# CMS32M6510 register map
Vendor: CMS; Series: CMS32M6510; File version: 1.2
CPU: CM0+ r0p1, little endian, no MPU, no FPU, VTOR, 2 interrupt priority bits
Registers are 32-bit, read-write, reset 0x0 unless marked. A register's access mark holds for its fields unless they carry their own. Offsets are from the block's base; [hi:lo] are bit positions; {n}, {i} and the like mark numbered series; 'fields as' and 'values as' point back to an identical list.

## LVD — Voltage detector
Base 0x40020440
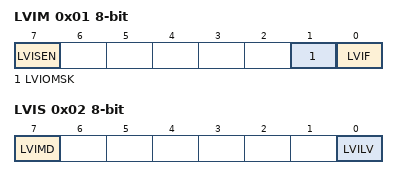
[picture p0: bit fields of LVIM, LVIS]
0x01 LVIM 8-bit — Voltage detection register
  [7] LVISEN ro — Enable rewritting LVIS register
    0=Disable (Disabling of rewriting the LVIS register); 1=Enable (Enabling of rewriting the LVIS register)
  [1] LVIOMSK ro — Mask status flag of LVD output
    0=Invalid (Mask of LVD output is invalid); 1=Valid (Mask of LVD output is valid)
  [0] LVIF ro — Voltage detection flag
    0=GE (Supply voltage (VDD) greater or equal to detection voltage (VLVD), or when LVD is off); 1=LT (Supply voltage (VDD) less than detection voltage (VLVD))
0x02 LVIS 8-bit — Voltage detection level register
  [7] LVIMD — Operation mode of voltage detection
    0=IRQ (interrupt mode); 1=reset mode
  [0] LVILV — LVD detection level
    0=High-voltage detection level (VLVDH); 1=Low (Low-voltage detection level (VLVDL or VLVD))

## PCBZ — Clock/Buzzer output controller
Base 0x40040FA0
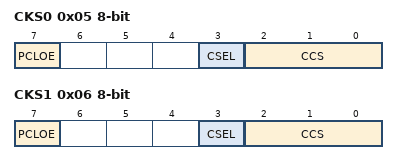
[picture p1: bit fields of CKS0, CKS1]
0x05 CKS0 8-bit — Clock output select registers 0
  [7] PCLOE — PCLBUZn pin output enable
  [3] CSEL — PCLBUZn output clock select
  [2:0] CCS — PCLBUZn output clock select
0x06 CKS1 8-bit — Clock output select registers 1
  fields as CKS0

## WDT — Watchdog Timer with window
Base 0x40020404
0x01 LOCKCTL 8-bit (reset mask 0x1) — Lockup Watchdog timer enable register
0x02 PRCR 8-bit — Lockup Watchdog timer enable protect register
0xBFD WDTE 8-bit (reset mask 0xAC) — Watchdog timer enable register

## TIMER0 — TIMER0 Decription
Base 0x40061000
Same registers: TIMER1 0x40061100
0x00 CON reset 0x20 — CON Description
0x04 LOAD — LOAD Description
0x08 VAL ro reset 0xFFFFFFFF — VAL Description
0x0C RIS ro — RIS Description
0x10 MIS ro — MIS Description
0x14 ICLR wo — ICLR Description
0x18 BGLOAD — BGLOAD Description

## LSITIMER
Base 0x40044B50
0x00 CON0 16-bit — Control Register 0

## EPWM — EPWM Decription
Base 0x40064200
0x00 CLKPSC — CLKPSC Description
0x04 CLKDIV — CLKDIV Description
0x08 CON — CON Description
0x0C CON2 — CON2 Description
0x10 CON3 — CON3 Description
{0x14+4i} PERIOD{i} (i=0..5) — PERIOD{i} Description
{0x2C+4i} CMPDAT{i} (i=0..5) — CMPDAT{i} Description
0x44 POREMAP — POREMAP Description
0x48 POEN reset 0x543210 — POEN Description
0x4C BRKCTL — BRKCTL Description
0x50 DTCTL — DTCTL Description
0x54 MASK — MASK Description
0x58 MASKNXT — MASKNXT Description
0x5C CMPTGD0 — CMPTGD0 Description
0x60 CMPTGD1 — CMPTGD1 Description
0x64 IMSC — IMSC Description
0x68 RIS ro — RIS Description
0x6C MIS ro — MIS Description
0x70 ICLR wo — ICLR Description
0x74 IFA — IFA Description
0x78 LOCK — LOCK Description

## CCP — CCP Decription
Base 0x40064280
0x00 CCPCON0 — CCPCON0 Description
0x04 CCPLOAD0 — CCPLOAD0 Description
0x08 CCPD0A — CCPD0A Description
0x0C CCPD0B — CCPD0B Description
0x10 CCPCON1 — CCPCON1 Description
0x14 CCPLOAD1 — CCPLOAD1 Description
0x18 CCPD1A — CCPD1A Description
0x1C CCPD1B — CCPD1B Description
0x40 CCPIMSC — CCPIMSC Description
0x44 CCPRIS ro — CCPRIS Description
0x48 CCPMIS ro — CCPMIS Description
0x4C CCPICLR wo — CCPICLR Description
0x50 CCPRUN — CCPRUN Description
0x54 CCPLOCK — CCPLOCK Description
0x58 CAPCON — CAPCON Description
0x5C CAPCHS — CAPCHS Description
{0x60+4i} CAP{i}DAT0 (i=0..3) — CAP{i}DAT0 Description

## UART0 — UART0 Decription
Base 0x40064000
0x00 UART0RBR ro — UART0RBR Description
0x04 UART0THR wo — UART0THR Description
0x08 UART0DLR reset 0x1 — UART0DLR Description
0x0C UART0IER — UART0IER Description
0x10 UART0IIR ro reset 0x1 — UART0IIR Description
0x14 UART0FCR wo — UART0FCR Description
0x18 UART0LCR — UART0LCR Description
0x1C UART0MCR — UART0MCR Description
0x20 UART0LSR ro reset 0x60 — UART0LSR Description
0x24 UART0MSR ro — UART0MSR Description
0x28 UART0SCR — UART0SCR Description
0x2C UART0EFR — UART0EFR Description
0x30 UART0XON1 — UART0XON1 Description
0x34 UART0XON2 — UART0XON2 Description
0x38 UART0XOFF1 — UART0XOFF1 Description
0x3C UART0END — UART0END Description

## Notices in the file
Copyright (C) 2012-2014 ARM Limited. All rights reserved.
Purpose: System Viewer Description (SVD) Example (Schema Version 1.1)
This is a description of a none-existent and incomplete device
for demonstration purposes only.
Redistribution and use in source and binary forms, with or without
modification, are permitted provided that the following conditions are met:
- Redistributions of source code must retain the above copyright
notice, this list of conditions and the following disclaimer.
- Redistributions in binary form must reproduce the above copyright
notice, this list of conditions and the following disclaimer in the
documentation and/or other materials provided with the distribution.
- Neither the name of ARM nor the names of its contributors may be used
to endorse or promote products derived from this software without
specific prior written permission.
THIS SOFTWARE IS PROVIDED BY THE COPYRIGHT HOLDERS AND CONTRIBUTORS "AS IS"
AND ANY EXPRESS OR IMPLIED WARRANTIES, INCLUDING, BUT NOT LIMITED TO, THE
IMPLIED WARRANTIES OF MERCHANTABILITY AND FITNESS FOR A PARTICULAR PURPOSE
ARE DISCLAIMED. IN NO EVENT SHALL COPYRIGHT HOLDERS AND CONTRIBUTORS BE
LIABLE FOR ANY DIRECT, INDIRECT, INCIDENTAL, SPECIAL, EXEMPLARY, OR
CONSEQUENTIAL DAMAGES (INCLUDING, BUT NOT LIMITED TO, PROCUREMENT OF
SUBSTITUTE GOODS OR SERVICES; LOSS OF USE, DATA, OR PROFITS; OR BUSINESS
INTERRUPTION) HOWEVER CAUSED AND ON ANY THEORY OF LIABILITY, WHETHER IN
CONTRACT, STRICT LIABILITY, OR TORT (INCLUDING NEGLIGENCE OR OTHERWISE)
ARISING IN ANY WAY OUT OF THE USE OF THIS SOFTWARE, EVEN IF ADVISED OF THE
POSSIBILITY OF SUCH DAMAGE.
